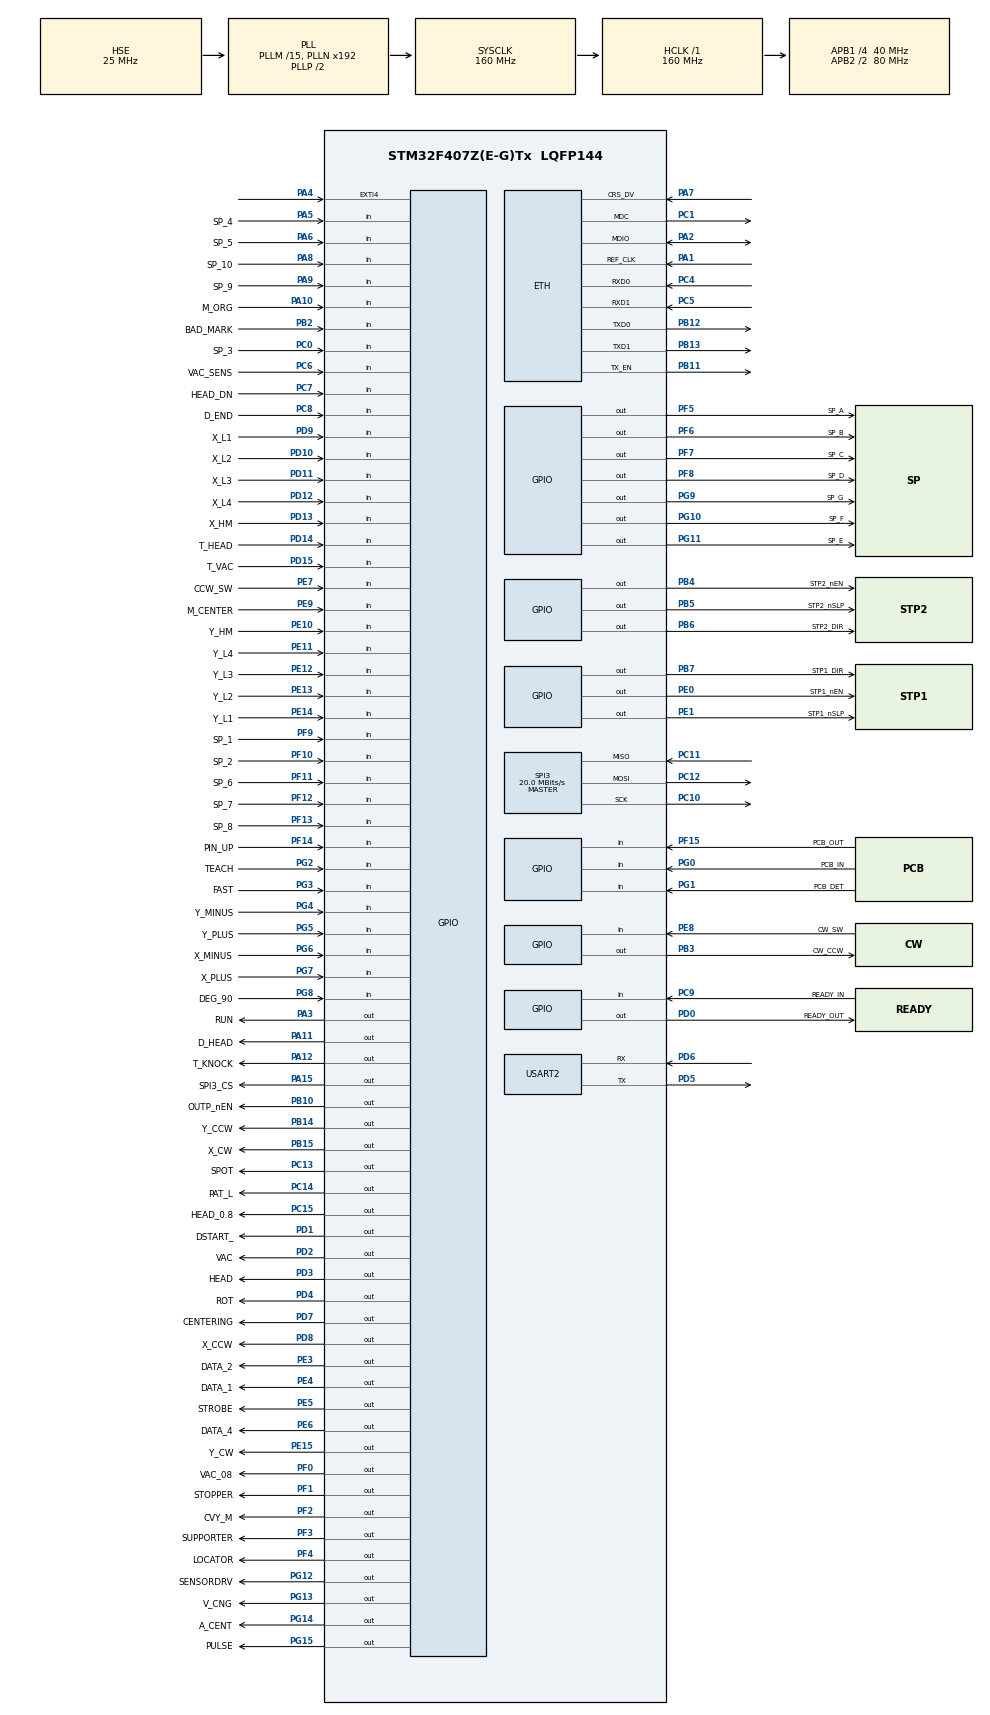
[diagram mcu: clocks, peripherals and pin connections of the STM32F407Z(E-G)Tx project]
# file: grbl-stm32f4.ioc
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ETH.MediaInterface=ETH_MEDIA_INTERFACE_RMII
Mcu.Family=STM32F4
Mcu.Name=STM32F407Z(E-G)Tx
Mcu.Package=LQFP144
NVIC.ETH_WKUP_IRQn=true\:0\:0\:false\:false\:true\:true\:true
NVIC.PriorityGroup=NVIC_PRIORITYGROUP_4
NVIC.TIM2_IRQn=true\:0\:0\:false\:false\:true\:true\:true
NVIC.TIM3_IRQn=true\:0\:0\:false\:false\:true\:true\:true
NVIC.TIM8_TRG_COM_TIM14_IRQn=true\:0\:0\:false\:false\:true\:true\:true
NVIC.USART2_IRQn=true\:0\:0\:false\:false\:true\:true\:true
PA1.Mode=RMII
PA1.Signal=ETH_REF_CLK
PA10.GPIO_Label=M_ORG
PA10.GPIO_PuPd=GPIO_PULLUP
PA10.Signal=GPIO_Input
PA11.GPIO_Label=D_HEAD
PA11.Signal=GPIO_Output
PA12.GPIO_Label=T_KNOCK
PA12.Signal=GPIO_Output
PA13.Mode=Serial_Wire
PA13.Signal=SYS_JTMS-SWDIO
PA14.Mode=Serial_Wire
PA14.Signal=SYS_JTCK-SWCLK
PA15.GPIO_Label=SPI3_CS
PA15.Signal=GPIO_Output
PA2.Mode=RMII
PA2.Signal=ETH_MDIO
PA3.GPIO_Label=RUN
PA3.Signal=GPIO_Output
PA4.Signal=GPXTI4
PA5.GPIO_Label=SP_4
PA5.GPIO_PuPd=GPIO_PULLUP
PA5.Signal=GPIO_Input
PA6.GPIO_Label=SP_5
PA6.GPIO_PuPd=GPIO_PULLUP
PA6.Signal=GPIO_Input
PA7.Mode=RMII
PA7.Signal=ETH_CRS_DV
PA8.GPIO_Label=SP_10
PA8.GPIO_PuPd=GPIO_PULLUP
PA8.Signal=GPIO_Input
PA9.GPIO_Label=SP_9
PA9.GPIO_PuPd=GPIO_PULLUP
PA9.Signal=GPIO_Input
PB10.GPIO_Label=OUTP_nEN
PB10.Signal=GPIO_Output
PB11.Mode=RMII
PB11.Signal=ETH_TX_EN
PB12.Mode=RMII
PB12.Signal=ETH_TXD0
PB13.Mode=RMII
PB13.Signal=ETH_TXD1
PB14.GPIO_Label=Y_CCW
PB14.GPIO_Speed=GPIO_SPEED_FREQ_VERY_HIGH
PB14.PinState=GPIO_PIN_SET
PB14.Signal=GPIO_Output
PB15.GPIO_Label=X_CW
PB15.GPIO_Speed=GPIO_SPEED_FREQ_VERY_HIGH
PB15.PinState=GPIO_PIN_SET
PB15.Signal=GPIO_Output
PB2.GPIO_Label=BAD_MARK
PB2.GPIO_PuPd=GPIO_PULLUP
PB2.Signal=GPIO_Input
PB3.GPIO_Label=CW_CCW
PB3.Signal=GPIO_Output
PB4.GPIO_Label=STP2_nEN
PB4.Signal=GPIO_Output
PB5.GPIO_Label=STP2_nSLP
PB5.Signal=GPIO_Output
PB6.GPIO_Label=STP2_DIR
PB6.Signal=GPIO_Output
PB7.GPIO_Label=STP1_DIR
PB7.Signal=GPIO_Output
PB8.GPIO_Label=STP2_STP
PB8.Signal=S_TIM4_CH3
PB9.GPIO_Label=STP1_STP
PB9.Signal=S_TIM4_CH4
PC0.GPIO_Label=SP_3
PC0.GPIO_PuPd=GPIO_PULLUP
PC0.Signal=GPIO_Input
PC1.Mode=RMII
PC1.Signal=ETH_MDC
PC10.Mode=Full_Duplex_Master
PC10.Signal=SPI3_SCK
PC11.Mode=Full_Duplex_Master
PC11.Signal=SPI3_MISO
PC12.Mode=Full_Duplex_Master
PC12.Signal=SPI3_MOSI
PC13-ANTI_TAMP.GPIO_Label=SPOT
PC13-ANTI_TAMP.Signal=GPIO_Output
PC14-OSC32_IN.GPIO_Label=PAT_L
PC14-OSC32_IN.Signal=GPIO_Output
PC15-OSC32_OUT.GPIO_Label=HEAD_0.8
PC15-OSC32_OUT.Signal=GPIO_Output
PC4.Mode=RMII
PC4.Signal=ETH_RXD0
PC5.Mode=RMII
PC5.Signal=ETH_RXD1
PC6.GPIO_Label=VAC_SENS
PC6.GPIO_PuPd=GPIO_PULLUP
PC6.Signal=GPIO_Input
PC7.GPIO_Label=HEAD_DN
PC7.GPIO_PuPd=GPIO_PULLUP
PC7.Signal=GPIO_Input
PC8.GPIO_Label=D_END
PC8.GPIO_PuPd=GPIO_PULLUP
PC8.Signal=GPIO_Input
PC9.GPIO_Label=READY_IN
PC9.GPIO_PuPd=GPIO_PULLUP
PC9.Signal=GPIO_Input
PD0.GPIO_Label=READY_OUT
PD0.Signal=GPIO_Output
PD1.GPIO_Label=DSTART_
PD1.Signal=GPIO_Output
PD10.GPIO_Label=X_L2
PD10.GPIO_PuPd=GPIO_PULLUP
PD10.Signal=GPIO_Input
PD11.GPIO_Label=X_L3
PD11.GPIO_PuPd=GPIO_PULLUP
PD11.Signal=GPIO_Input
PD12.GPIO_Label=X_L4
PD12.GPIO_PuPd=GPIO_PULLUP
PD12.Signal=GPIO_Input
PD13.GPIO_Label=X_HM
PD13.GPIO_PuPd=GPIO_PULLUP
PD13.Signal=GPIO_Input
PD14.GPIO_Label=T_HEAD
PD14.GPIO_PuPd=GPIO_PULLUP
PD14.Signal=GPIO_Input
PD15.GPIO_Label=T_VAC
PD15.GPIO_PuPd=GPIO_PULLUP
PD15.Signal=GPIO_Input
PD2.GPIO_Label=VAC
PD2.GPIO_PuPd=GPIO_NOPULL
PD2.Signal=GPIO_Output
PD3.GPIO_Label=HEAD
PD3.Signal=GPIO_Output
PD4.GPIO_Label=ROT
PD4.Signal=GPIO_Output
PD5.Mode=Asynchronous
PD5.Signal=USART2_TX
PD6.Mode=Asynchronous
PD6.Signal=USART2_RX
PD7.GPIO_Label=CENTERING
PD7.Signal=GPIO_Output
PD8.GPIO_Label=X_CCW
PD8.GPIO_Speed=GPIO_SPEED_FREQ_VERY_HIGH
PD8.PinState=GPIO_PIN_SET
PD8.Signal=GPIO_Output
PD9.GPIO_Label=X_L1
PD9.GPIO_PuPd=GPIO_PULLUP
PD9.Signal=GPIO_Input
PE0.GPIO_Label=STP1_nEN
PE0.Signal=GPIO_Output
PE1.GPIO_Label=STP1_nSLP
PE1.Signal=GPIO_Output
PE10.GPIO_Label=Y_HM
PE10.GPIO_PuPd=GPIO_PULLUP
PE10.Signal=GPIO_Input
PE11.GPIO_Label=Y_L4
PE11.GPIO_PuPd=GPIO_PULLUP
PE11.Signal=GPIO_Input
PE12.GPIO_Label=Y_L3
PE12.GPIO_PuPd=GPIO_PULLUP
PE12.Signal=GPIO_Input
PE13.GPIO_Label=Y_L2
PE13.GPIO_PuPd=GPIO_PULLUP
PE13.Signal=GPIO_Input
PE14.GPIO_Label=Y_L1
PE14.GPIO_PuPd=GPIO_PULLUP
PE14.Signal=GPIO_Input
PE15.GPIO_Label=Y_CW
PE15.GPIO_Speed=GPIO_SPEED_FREQ_VERY_HIGH
PE15.PinState=GPIO_PIN_SET
PE15.Signal=GPIO_Output
PE3.GPIO_Label=DATA_2
PE3.Signal=GPIO_Output
PE4.GPIO_Label=DATA_1
PE4.Signal=GPIO_Output
PE5.GPIO_Label=STROBE
PE5.Signal=GPIO_Output
PE6.GPIO_Label=DATA_4
PE6.Signal=GPIO_Output
PE7.GPIO_Label=CCW_SW
PE7.GPIO_PuPd=GPIO_PULLUP
PE7.Signal=GPIO_Input
PE8.GPIO_Label=CW_SW
PE8.GPIO_PuPd=GPIO_PULLUP
PE8.Signal=GPIO_Input
PE9.GPIO_Label=M_CENTER
PE9.GPIO_PuPd=GPIO_PULLUP
PE9.Signal=GPIO_Input
PF0.GPIO_Label=VAC_08
PF0.Signal=GPIO_Output
PF1.GPIO_Label=STOPPER
PF1.Signal=GPIO_Output
PF10.GPIO_Label=SP_2
PF10.GPIO_PuPd=GPIO_PULLUP
PF10.Signal=GPIO_Input
PF11.GPIO_Label=SP_6
PF11.GPIO_PuPd=GPIO_PULLUP
PF11.Signal=GPIO_Input
PF12.GPIO_Label=SP_7
PF12.GPIO_PuPd=GPIO_PULLUP
PF12.Signal=GPIO_Input
PF13.GPIO_Label=SP_8
PF13.GPIO_PuPd=GPIO_PULLUP
PF13.Signal=GPIO_Input
PF14.GPIO_Label=PIN_UP
PF14.GPIO_PuPd=GPIO_PULLUP
PF14.Signal=GPIO_Input
PF15.GPIO_Label=PCB_OUT
PF15.GPIO_PuPd=GPIO_PULLUP
PF15.Signal=GPIO_Input
PF2.GPIO_Label=CVY_M
PF2.Signal=GPIO_Output
PF3.GPIO_Label=SUPPORTER
PF3.Signal=GPIO_Output
PF4.GPIO_Label=LOCATOR
PF4.Signal=GPIO_Output
PF5.GPIO_Label=SP_A
PF5.Signal=GPIO_Output
PF6.GPIO_Label=SP_B
PF6.Signal=GPIO_Output
PF7.GPIO_Label=SP_C
PF7.Signal=GPIO_Output
PF8.GPIO_Label=SP_D
PF8.Signal=GPIO_Output
PF9.GPIO_Label=SP_1
PF9.GPIO_PuPd=GPIO_PULLUP
PF9.Signal=GPIO_Input
PG0.GPIO_Label=PCB_IN
PG0.GPIO_PuPd=GPIO_PULLUP
PG0.Signal=GPIO_Input
PG1.GPIO_Label=PCB_DET
PG1.GPIO_PuPd=GPIO_PULLUP
PG1.Signal=GPIO_Input
PG10.GPIO_Label=SP_F
PG10.Signal=GPIO_Output
PG11.GPIO_Label=SP_E
PG11.Signal=GPIO_Output
PG12.GPIO_Label=SENSORDRV
PG12.Signal=GPIO_Output
PG13.GPIO_Label=V_CNG
PG13.Signal=GPIO_Output
PG14.GPIO_Label=A_CENT
PG14.Signal=GPIO_Output
PG15.GPIO_Label=PULSE
PG15.Signal=GPIO_Output
PG2.GPIO_Label=TEACH
PG2.GPIO_PuPd=GPIO_PULLUP
PG2.Signal=GPIO_Input
PG3.GPIO_Label=FAST
PG3.GPIO_PuPd=GPIO_PULLUP
PG3.Signal=GPIO_Input
PG4.GPIO_Label=Y_MINUS
PG4.GPIO_PuPd=GPIO_PULLUP
PG4.Signal=GPIO_Input
PG5.GPIO_Label=Y_PLUS
PG5.GPIO_PuPd=GPIO_PULLUP
PG5.Signal=GPIO_Input
PG6.GPIO_Label=X_MINUS
PG6.GPIO_PuPd=GPIO_PULLUP
PG6.Signal=GPIO_Input
PG7.GPIO_Label=X_PLUS
PG7.GPIO_PuPd=GPIO_PULLUP
PG7.Signal=GPIO_Input
PG8.GPIO_Label=DEG_90
PG8.GPIO_PuPd=GPIO_PULLUP
PG8.Signal=GPIO_Input
PG9.GPIO_Label=SP_G
PG9.Signal=GPIO_Output
PH0-OSC_IN.Mode=HSE-External-Oscillator
PH0-OSC_IN.Signal=RCC_OSC_IN
PH1-OSC_OUT.Mode=HSE-External-Oscillator
PH1-OSC_OUT.Signal=RCC_OSC_OUT
ProjectManager.HeapSize=0x200
ProjectManager.StackSize=0x400
ProjectManager.TargetToolchain=STM32CubeIDE
RCC.48MHZClocksFreq_Value=80000000
RCC.AHBFreq_Value=160000000
RCC.APB1CLKDivider=RCC_HCLK_DIV4
RCC.APB1Freq_Value=40000000
RCC.APB1TimFreq_Value=80000000
RCC.APB2CLKDivider=RCC_HCLK_DIV2
RCC.APB2Freq_Value=80000000
RCC.APB2TimFreq_Value=160000000
RCC.CortexFreq_Value=160000000
RCC.HCLKFreq_Value=160000000
RCC.HSE_VALUE=25000000
RCC.HSI_VALUE=16000000
RCC.LSE_VALUE=32768
RCC.PLLM=15
RCC.PLLSourceVirtual=RCC_PLLSOURCE_HSE
RCC.SYSCLKFreq_VALUE=160000000
RCC.SYSCLKSource=RCC_SYSCLKSOURCE_PLLCLK
RCC.VCOOutputFreq_Value=320000000
SH.S_TIM4_CH3.0=TIM4_CH3
SH.S_TIM4_CH4.0=TIM4_CH4
SPI3.BaudRatePrescaler=SPI_BAUDRATEPRESCALER_2
SPI3.CalculateBaudRate=20.0 MBits/s
SPI3.Direction=SPI_DIRECTION_2LINES
SPI3.Mode=SPI_MODE_MASTER
SPI3.VirtualType=VM_MASTER
TIM14.AutoReloadPreload=TIM_AUTORELOAD_PRELOAD_ENABLE
TIM14.ClockDivision=TIM_CLOCKDIVISION_DIV1
TIM14.Period=1000
TIM14.Prescaler=100
TIM2.ClockDivision=TIM_CLOCKDIVISION_DIV1
TIM2.Period=1000
TIM3.AutoReloadPreload=TIM_AUTORELOAD_PRELOAD_DISABLE
TIM3.ClockDivision=TIM_CLOCKDIVISION_DIV1
TIM3.Period=10
TIM3.Prescaler=16
USART2.VirtualMode=VM_ASYNC
VP_TIM14_VS_ClockSourceINT.Mode=Enable_Timer
VP_TIM2_VS_ClockSourceINT.Mode=Internal
VP_TIM2_VS_ClockSourceITR.Mode=TriggerSource_ITR0
VP_TIM3_VS_ClockSourceINT.Mode=Internal
VP_TIM3_VS_ClockSourceITR.Mode=TriggerSource_ITR0
board=custom

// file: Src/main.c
/* USER CODE BEGIN Header */
/**
 ******************************************************************************
 * @file           : main.c
 * @brief          : Main program body
 ******************************************************************************
 * @attention
 *
 * <h2><center>&copy; Copyright (c) 2019 STMicroelectronics.
 * All rights reserved.</center></h2>
 *
 * This software component is licensed by ST under BSD 3-Clause license,
 * the "License"; You may not use this file except in compliance with the
 * License. You may obtain a copy of the License at:
 *                        opensource.org/licenses/BSD-3-Clause
 *
 ******************************************************************************

 main.c - An embedded CNC Controller with rs274/ngc (g-code) support
 Part of Grbl-Advanced

 Copyright (c) 2011-2016 Sungeun K. Jeon for Gnea Research LLC
 Copyright (c) 2009-2011 Simen Svale Skogsrud
 Copyright (c)	2017 Patrick F.

 Grbl-Advanced is free software: you can redistribute it and/or modify
 it under the terms of the GNU General Public License as published by
 the Free Software Foundation, either version 3 of the License, or
 (at your option) any later version.
 Grbl-Advanced is distributed in the hope that it will be useful,
 but WITHOUT ANY WARRANTY; without even the implied warranty of
 MERCHANTABILITY or FITNESS FOR A PARTICULAR PURPOSE.  See the
 GNU General Public License for more details.
 You should have received a copy of the GNU General Public License
 along with Grbl-Advanced.  If not, see <http://www.gnu.org/licenses/>.

 */
/* USER CODE END Header */

#include "main.h"

/* USER CODE BEGIN Includes */
#include "SEGGER_SYSVIEW.h"

#include <stdio.h>
#include <stdlib.h>
#include <stdint.h>

#include "system.h"
#include "grbl.h"

#include "print.h"

#define ACTUATOR_LIMIT 31 // define 31 output pins for hardware M42 command
#include "cpu_map_stm32.h"
/* USER CODE END Includes */

ETH_HandleTypeDef heth;

SPI_HandleTypeDef hspi3;

TIM_HandleTypeDef htim2;
TIM_HandleTypeDef htim3;
TIM_HandleTypeDef htim14;

UART_HandleTypeDef huart2;

/* USER CODE BEGIN PV */
system_t sys;
int32_t sys_position[N_AXIS]; // Real-time machine (aka home) position vector in steps.
int32_t sys_probe_position[N_AXIS]; // Last probe position in machine coordinates and steps.
volatile uint8_t sys_probe_state; // Probing state value.  Used to coordinate the probing cycle with stepper ISR.
volatile uint8_t sys_rt_exec_state; // Global realtime executor bitflag variable for state management. See EXEC bitmasks.
volatile uint8_t sys_rt_exec_alarm; // Global realtime executor bitflag variable for setting various alarms.
volatile uint8_t sys_rt_exec_motion_override; // Global realtime executor bitflag variable for motion-based overrides.
volatile uint8_t sys_rt_exec_accessory_override; // Global realtime executor bitflag variable for spindle/coolant overrides.
#ifdef DEBUG
volatile uint8_t sys_rt_exec_debug;
#endif
uint8_t rx_byte;
/* USER CODE END PV */

void SystemClock_Config(void);
static void MX_GPIO_Init(void);
static void MX_ETH_Init(void);
static void MX_SPI3_Init(void);
static void MX_USART2_UART_Init(void);
static void MX_TIM2_Init(void);
static void MX_TIM3_Init(void);
static void MX_TIM14_Init(void);

/* USER CODE BEGIN 0 */
// Actuators that can be controlled with M42
const gpio actuators[] = {
/* 0 */	{.port = VAC_GPIO_Port, .pin= VAC_Pin},
/* 1 */	{.port = HEAD_GPIO_Port, .pin= HEAD_Pin},
/* 2 */	{.port = ROT_GPIO_Port, .pin= ROT_Pin},
/* 3 */	{.port = CENTERING_GPIO_Port, .pin= CENTERING_Pin},
/* 4 */	{.port = STROBE_GPIO_Port, .pin = STROBE_Pin},
/* 5 */	{.port = STOPPER_GPIO_Port, .pin = STOPPER_Pin},
/* 6 */	{.port = DATA_1_GPIO_Port, .pin = DATA_1_Pin},
/* 7 */	{.port = DATA_2_GPIO_Port, .pin = DATA_2_Pin},
/* 8 */	{.port = DATA_4_GPIO_Port, .pin = DATA_4_Pin},
/* 9 */	{.port = VAC_08_GPIO_Port, .pin = VAC_08_Pin},
/* 10 */{.port = HEAD_0_8_GPIO_Port, .pin = HEAD_0_8_Pin},
/* 11 */{.port = D_HEAD_GPIO_Port, .pin = D_HEAD_Pin},
/* 12 */{.port = T_KNOCK_GPIO_Port, .pin = T_KNOCK_Pin},
/* 13 */{.port = SPOT_GPIO_Port, .pin = SPOT_Pin},
/* 14 */{.port = PAT_L_GPIO_Port, .pin = PAT_L_Pin},
/* 15 */{.port = READY_OUT_GPIO_Port, .pin = READY_OUT_Pin},
/* 16 */{.port = DSTART__GPIO_Port, .pin = DSTART__Pin},
/* 17 */{.port = CVY_M_GPIO_Port, .pin = CVY_M_Pin},
/* 18 */{.port = SUPPORTER_GPIO_Port, .pin = SUPPORTER_Pin},
/* 19 */{.port = LOCATOR_GPIO_Port, .pin = LOCATOR_Pin},
/* 20 */{.port = SP_A_GPIO_Port, .pin = SP_A_Pin},
/* 21 */{.port = SP_B_GPIO_Port, .pin = SP_B_Pin},
/* 22 */{.port = SP_C_GPIO_Port, .pin = SP_C_Pin},
/* 23 */{.port = SP_D_GPIO_Port, .pin = SP_D_Pin},
/* 24 */{.port = SP_E_GPIO_Port, .pin = SP_E_Pin},
/* 25 */{.port = SP_F_GPIO_Port, .pin = SP_F_Pin},
/* 26 */{.port = SP_G_GPIO_Port, .pin = SP_G_Pin},
/* 27 */{.port = SENSORDRV_GPIO_Port, .pin = SENSORDRV_Pin},
/* 28 */{.port = V_CNG_GPIO_Port, .pin = V_CNG_Pin},
/* 29 */{.port = A_CENT_GPIO_Port, .pin = A_CENT_Pin},
/* 30 */{.port = PULSE_GPIO_Port, .pin = PULSE_Pin},
};
const uint8_t actuators_limit = sizeof(actuators)/sizeof(gpio);

const gpio sensors[] = {
		{.port = VAC_SENS_GPIO_Port, .pin = VAC_SENS_Pin, .key = 'v'},
		{.port = T_VAC_GPIO_Port, .pin = T_VAC_Pin, .key = 'V'},
		{.port = T_HEAD_GPIO_Port, .pin = T_HEAD_Pin, .key = 'h'},
		{.port = BAD_MARK_GPIO_Port, .pin = BAD_MARK_Pin, .key = 'b'},
		{.port = CCW_SW_GPIO_Port, .pin = CCW_SW_Pin, .key = 'C'},
		{.port = CW_SW_GPIO_Port, .pin = CW_CCW_Pin, .key = 'c'},
		{.port = D_END_GPIO_Port, .pin = D_END_Pin, .key = 'd'},
		{.port = DEG_90_GPIO_Port, .pin = DEG_90_Pin, .key = 'D'},
		{.port = M_CENTER_GPIO_Port, .pin = M_CENTER_Pin, .key = 'm'},
		{.port = M_ORG_GPIO_Port, .pin = M_ORG_Pin, .key = 'M'},
		{.port = PCB_DET_GPIO_Port, .pin = PCB_DET_Pin, .key = 'P'},
		{.port = PCB_IN_GPIO_Port, .pin = PCB_IN_Pin, .key = 'I'},
		{.port = PCB_OUT_GPIO_Port, .pin = PCB_OUT_Pin, .key = 'O'},
		{.port = PIN_UP_GPIO_Port, .pin = PIN_UP_Pin, .key = 'u'},
		{.port = READY_IN_GPIO_Port, .pin = READY_IN_Pin, .key = 'r'},
};
const uint8_t sensors_limit = sizeof(sensors)/sizeof(gpio);
/* USER CODE END 0 */

int main(void)
{

  /* MCU Configuration--------------------------------------------------------*/

  /* Reset of all peripherals, Initializes the Flash interface and the Systick. */
  HAL_Init();

  /* Configure the system clock */
  SystemClock_Config();

  /* Initialize all configured peripherals */
  MX_GPIO_Init();
  MX_ETH_Init();
  MX_SPI3_Init();
  MX_USART2_UART_Init();
  MX_TIM2_Init();
  MX_TIM3_Init();
  MX_TIM14_Init();
  /* USER CODE BEGIN 2 */

  SEGGER_SYSVIEW_Conf(); // Configure and initialize SystemView
  SEGGER_SYSVIEW_OnIdle();

  // Initialize grbl system upon power-up.
  settings_init(); // Load Grbl settings from EEPROM
  stepper_init();  // Configure stepper pins and interrupt timers
  system_init();   // Configure pinout pins and pin-change interrupt

	memset(sys_position, 0, sizeof(sys_position)); // Clear machine position.
	// Initialize system state.
#ifdef FORCE_INITIALIZATION_ALARM
	// Force Grbl into an ALARM state upon a power-cycle or hard reset.
	sys.state = STATE_ALARM;
#else
	sys.state = STATE_IDLE;
#endif

	// Check for power-up and set system alarm if homing is enabled to force homing cycle
	// by setting Grbl's alarm state. Alarm locks out all g-code commands, including the
	// startup scripts, but allows access to settings and internal commands. Only a homing
	// cycle '$H' or kill alarm locks '$X' will disable the alarm.
	// NOTE: The startup script will run after successful completion of the homing cycle, but
	// not after disabling the alarm locks. Prevents motion startup blocks from crashing into
	// things uncontrollably. Very bad.
#ifdef HOMING_INIT_LOCK
	if (bit_istrue(settings.flags, BITFLAG_HOMING_ENABLE)) {
		sys.state = STATE_ALARM;
	}
#endif

	// Grbl initialization loop upon power-up or a system abort. For the latter, all processes
	// will return to this loop to be cleanly re-initialized.

	// Reset system variables.
	uint8_t prior_state = sys.state;
	memset(&sys, 0, sizeof(system_t)); // Clear system struct variable.
	sys.state = prior_state;
	sys.f_override = DEFAULT_FEED_OVERRIDE;  // Set to 100%
	sys.r_override = DEFAULT_RAPID_OVERRIDE; // Set to 100%
	sys.spindle_speed_ovr = DEFAULT_SPINDLE_SPEED_OVERRIDE; // Set to 100%
	memset(sys_probe_position, 0, sizeof(sys_probe_position)); // Clear probe position.
	sys_probe_state = 0;
	sys_rt_exec_state = 0;
	sys_rt_exec_alarm = 0;
	sys_rt_exec_motion_override = 0;
	sys_rt_exec_accessory_override = 0;

	// Reset Grbl primary systems.
	serial_reset_read_buffer(); // Clear serial read buffer
	gc_init(); // Set g-code parser to default state
	//spindle_init();
	//coolant_init();
	//limits_init(); // Done in CubeMX
	//probe_init();
	plan_reset(); // Clear block buffer and planner variables
	st_reset(); // Clear stepper subsystem variables.

	// Sync cleared gcode and planner positions to current system position.
	plan_sync_position();
	gc_sync_position();

	// Print welcome message. Indicates an initialization has occured at power-up or with a reset.
	report_init_message();
	HAL_UART_Receive_IT(&huart2, &rx_byte, 1);
  /* USER CODE END 2 */

  /* Infinite loop */
  /* USER CODE BEGIN WHILE */
	// Start Grbl main loop. Processes program inputs and executes them.
	protocol_main_loop();
    /* USER CODE END WHILE */

}

void SystemClock_Config(void)
{
  RCC_OscInitTypeDef RCC_OscInitStruct = {0};
  RCC_ClkInitTypeDef RCC_ClkInitStruct = {0};

  /** Configure the main internal regulator output voltage
  */
  __HAL_RCC_PWR_CLK_ENABLE();
  __HAL_PWR_VOLTAGESCALING_CONFIG(PWR_REGULATOR_VOLTAGE_SCALE1);
  /** Initializes the CPU, AHB and APB busses clocks
  */
  RCC_OscInitStruct.OscillatorType = RCC_OSCILLATORTYPE_HSE;
  RCC_OscInitStruct.HSEState = RCC_HSE_ON;
  RCC_OscInitStruct.PLL.PLLState = RCC_PLL_ON;
  RCC_OscInitStruct.PLL.PLLSource = RCC_PLLSOURCE_HSE;
  RCC_OscInitStruct.PLL.PLLM = 15;
  RCC_OscInitStruct.PLL.PLLN = 192;
  RCC_OscInitStruct.PLL.PLLP = RCC_PLLP_DIV2;
  RCC_OscInitStruct.PLL.PLLQ = 4;
  if (HAL_RCC_OscConfig(&RCC_OscInitStruct) != HAL_OK)
  {
    Error_Handler();
  }
  /** Initializes the CPU, AHB and APB busses clocks
  */
  RCC_ClkInitStruct.ClockType = RCC_CLOCKTYPE_HCLK|RCC_CLOCKTYPE_SYSCLK
                              |RCC_CLOCKTYPE_PCLK1|RCC_CLOCKTYPE_PCLK2;
  RCC_ClkInitStruct.SYSCLKSource = RCC_SYSCLKSOURCE_PLLCLK;
  RCC_ClkInitStruct.AHBCLKDivider = RCC_SYSCLK_DIV1;
  RCC_ClkInitStruct.APB1CLKDivider = RCC_HCLK_DIV4;
  RCC_ClkInitStruct.APB2CLKDivider = RCC_HCLK_DIV2;

  if (HAL_RCC_ClockConfig(&RCC_ClkInitStruct, FLASH_LATENCY_5) != HAL_OK)
  {
    Error_Handler();
  }
}

static void MX_ETH_Init(void)
{

  heth.Instance = ETH;
  heth.Init.AutoNegotiation = ETH_AUTONEGOTIATION_ENABLE;
  heth.Init.PhyAddress = LAN8742A_PHY_ADDRESS;
  heth.Init.MACAddr[0] =   0x00;
  heth.Init.MACAddr[1] =   0x80;
  heth.Init.MACAddr[2] =   0xE1;
  heth.Init.MACAddr[3] =   0x00;
  heth.Init.MACAddr[4] =   0x00;
  heth.Init.MACAddr[5] =   0x00;
  heth.Init.RxMode = ETH_RXPOLLING_MODE;
  heth.Init.ChecksumMode = ETH_CHECKSUM_BY_HARDWARE;
  heth.Init.MediaInterface = ETH_MEDIA_INTERFACE_RMII;

  if (HAL_ETH_Init(&heth) != HAL_OK)
  {
    Error_Handler();
  }

}

static void MX_SPI3_Init(void)
{

  /* SPI3 parameter configuration*/
  hspi3.Instance = SPI3;
  hspi3.Init.Mode = SPI_MODE_MASTER;
  hspi3.Init.Direction = SPI_DIRECTION_2LINES;
  hspi3.Init.DataSize = SPI_DATASIZE_8BIT;
  hspi3.Init.CLKPolarity = SPI_POLARITY_LOW;
  hspi3.Init.CLKPhase = SPI_PHASE_1EDGE;
  hspi3.Init.NSS = SPI_NSS_SOFT;
  hspi3.Init.BaudRatePrescaler = SPI_BAUDRATEPRESCALER_2;
  hspi3.Init.FirstBit = SPI_FIRSTBIT_MSB;
  hspi3.Init.TIMode = SPI_TIMODE_DISABLE;
  hspi3.Init.CRCCalculation = SPI_CRCCALCULATION_DISABLE;
  hspi3.Init.CRCPolynomial = 10;
  if (HAL_SPI_Init(&hspi3) != HAL_OK)
  {
    Error_Handler();
  }

}

static void MX_TIM2_Init(void)
{

  TIM_ClockConfigTypeDef sClockSourceConfig = {0};
  TIM_SlaveConfigTypeDef sSlaveConfig = {0};
  TIM_MasterConfigTypeDef sMasterConfig = {0};

  htim2.Instance = TIM2;
  htim2.Init.Prescaler = 0;
  htim2.Init.CounterMode = TIM_COUNTERMODE_UP;
  htim2.Init.Period = 1000;
  htim2.Init.ClockDivision = TIM_CLOCKDIVISION_DIV1;
  htim2.Init.AutoReloadPreload = TIM_AUTORELOAD_PRELOAD_DISABLE;
  if (HAL_TIM_Base_Init(&htim2) != HAL_OK)
  {
    Error_Handler();
  }
  sClockSourceConfig.ClockSource = TIM_CLOCKSOURCE_INTERNAL;
  if (HAL_TIM_ConfigClockSource(&htim2, &sClockSourceConfig) != HAL_OK)
  {
    Error_Handler();
  }
  sSlaveConfig.SlaveMode = TIM_SLAVEMODE_DISABLE;
  sSlaveConfig.InputTrigger = TIM_TS_ITR0;
  if (HAL_TIM_SlaveConfigSynchro(&htim2, &sSlaveConfig) != HAL_OK)
  {
    Error_Handler();
  }
  sMasterConfig.MasterOutputTrigger = TIM_TRGO_RESET;
  sMasterConfig.MasterSlaveMode = TIM_MASTERSLAVEMODE_DISABLE;
  if (HAL_TIMEx_MasterConfigSynchronization(&htim2, &sMasterConfig) != HAL_OK)
  {
    Error_Handler();
  }
  /* USER CODE BEGIN TIM2_Init 2 */
HAL_TIM_Base_Start_IT(&htim2);
  /* USER CODE END TIM2_Init 2 */

}

static void MX_TIM3_Init(void)
{

  TIM_ClockConfigTypeDef sClockSourceConfig = {0};
  TIM_SlaveConfigTypeDef sSlaveConfig = {0};
  TIM_MasterConfigTypeDef sMasterConfig = {0};

  htim3.Instance = TIM3;
  htim3.Init.Prescaler = 2;
  htim3.Init.CounterMode = TIM_COUNTERMODE_UP;
  htim3.Init.Period = 10;
  htim3.Init.ClockDivision = TIM_CLOCKDIVISION_DIV1;
  htim3.Init.AutoReloadPreload = TIM_AUTORELOAD_PRELOAD_DISABLE;
  if (HAL_TIM_Base_Init(&htim3) != HAL_OK)
  {
    Error_Handler();
  }
  sClockSourceConfig.ClockSource = TIM_CLOCKSOURCE_INTERNAL;
  if (HAL_TIM_ConfigClockSource(&htim3, &sClockSourceConfig) != HAL_OK)
  {
    Error_Handler();
  }
  sSlaveConfig.SlaveMode = TIM_SLAVEMODE_DISABLE;
  sSlaveConfig.InputTrigger = TIM_TS_ITR0;
  if (HAL_TIM_SlaveConfigSynchro(&htim3, &sSlaveConfig) != HAL_OK)
  {
    Error_Handler();
  }
  sMasterConfig.MasterOutputTrigger = TIM_TRGO_RESET;
  sMasterConfig.MasterSlaveMode = TIM_MASTERSLAVEMODE_DISABLE;
  if (HAL_TIMEx_MasterConfigSynchronization(&htim3, &sMasterConfig) != HAL_OK)
  {
    Error_Handler();
  }
  /* USER CODE BEGIN TIM3_Init 2 */
HAL_TIM_Base_Start_IT(&htim3);
  /* USER CODE END TIM3_Init 2 */

}

static void MX_TIM14_Init(void)
{

  htim14.Instance = TIM14;
  htim14.Init.Prescaler = 100;
  htim14.Init.CounterMode = TIM_COUNTERMODE_UP;
  htim14.Init.Period = 1000;
  htim14.Init.ClockDivision = TIM_CLOCKDIVISION_DIV1;
  htim14.Init.AutoReloadPreload = TIM_AUTORELOAD_PRELOAD_ENABLE;
  if (HAL_TIM_Base_Init(&htim14) != HAL_OK)
  {
    Error_Handler();
  }
  /* USER CODE BEGIN TIM14_Init 2 */
  HAL_TIM_Base_Start_IT(&htim14); // Enable the input latch timer
  /* USER CODE END TIM14_Init 2 */

}

static void MX_USART2_UART_Init(void)
{

  huart2.Instance = USART2;
  huart2.Init.BaudRate = 115200;
  huart2.Init.WordLength = UART_WORDLENGTH_8B;
  huart2.Init.StopBits = UART_STOPBITS_1;
  huart2.Init.Parity = UART_PARITY_NONE;
  huart2.Init.Mode = UART_MODE_TX_RX;
  huart2.Init.HwFlowCtl = UART_HWCONTROL_NONE;
  huart2.Init.OverSampling = UART_OVERSAMPLING_16;
  if (HAL_UART_Init(&huart2) != HAL_OK)
  {
    Error_Handler();
  }

}

static void MX_GPIO_Init(void)
{
  GPIO_InitTypeDef GPIO_InitStruct = {0};

  /* GPIO Ports Clock Enable */
  __HAL_RCC_GPIOE_CLK_ENABLE();
  __HAL_RCC_GPIOC_CLK_ENABLE();
  __HAL_RCC_GPIOF_CLK_ENABLE();
  __HAL_RCC_GPIOH_CLK_ENABLE();
  __HAL_RCC_GPIOA_CLK_ENABLE();
  __HAL_RCC_GPIOB_CLK_ENABLE();
  __HAL_RCC_GPIOG_CLK_ENABLE();
  __HAL_RCC_GPIOD_CLK_ENABLE();

  /*Configure GPIO pin Output Level */
  HAL_GPIO_WritePin(GPIOE, DATA_2_Pin|DATA_1_Pin|STROBE_Pin|DATA_4_Pin
                          |STP1_nEN_Pin|STP1_nSLP_Pin, GPIO_PIN_RESET);

  /*Configure GPIO pin Output Level */
  HAL_GPIO_WritePin(GPIOC, SPOT_Pin|PAT_L_Pin|HEAD_0_8_Pin, GPIO_PIN_RESET);

  /*Configure GPIO pin Output Level */
  HAL_GPIO_WritePin(GPIOF, VAC_08_Pin|STOPPER_Pin|CVY_M_Pin|SUPPORTER_Pin
                          |LOCATOR_Pin|SP_A_Pin|SP_B_Pin|SP_C_Pin
                          |SP_D_Pin, GPIO_PIN_RESET);

  /*Configure GPIO pin Output Level */
  HAL_GPIO_WritePin(GPIOA, RUN_Pin|D_HEAD_Pin|T_KNOCK_Pin|SPI3_CS_Pin, GPIO_PIN_RESET);

  /*Configure GPIO pin Output Level */
  HAL_GPIO_WritePin(Y_CW_GPIO_Port, Y_CW_Pin, GPIO_PIN_SET);

  /*Configure GPIO pin Output Level */
  HAL_GPIO_WritePin(GPIOB, OUTP_nEN_Pin|CW_CCW_Pin|STP2_nEN_Pin|STP2_nSLP_Pin
                          |STP2_DIR_Pin|STP1_DIR_Pin, GPIO_PIN_RESET);

  /*Configure GPIO pin Output Level */
  HAL_GPIO_WritePin(GPIOB, Y_CCW_Pin|X_CW_Pin, GPIO_PIN_SET);

  /*Configure GPIO pin Output Level */
  HAL_GPIO_WritePin(X_CCW_GPIO_Port, X_CCW_Pin, GPIO_PIN_SET);

  /*Configure GPIO pin Output Level */
  HAL_GPIO_WritePin(GPIOD, READY_OUT_Pin|DSTART__Pin|VAC_Pin|HEAD_Pin
                          |ROT_Pin|CENTERING_Pin, GPIO_PIN_RESET);

  /*Configure GPIO pin Output Level */
  HAL_GPIO_WritePin(GPIOG, SP_G_Pin|SP_F_Pin|SP_E_Pin|SENSORDRV_Pin
                          |V_CNG_Pin|A_CENT_Pin|PULSE_Pin, GPIO_PIN_RESET);

  /*Configure GPIO pins : DATA_2_Pin DATA_1_Pin STROBE_Pin DATA_4_Pin
                           STP1_nEN_Pin STP1_nSLP_Pin */
  GPIO_InitStruct.Pin = DATA_2_Pin|DATA_1_Pin|STROBE_Pin|DATA_4_Pin
                          |STP1_nEN_Pin|STP1_nSLP_Pin;
  GPIO_InitStruct.Mode = GPIO_MODE_OUTPUT_PP;
  GPIO_InitStruct.Pull = GPIO_NOPULL;
  GPIO_InitStruct.Speed = GPIO_SPEED_FREQ_LOW;
  HAL_GPIO_Init(GPIOE, &GPIO_InitStruct);

  /*Configure GPIO pins : SPOT_Pin PAT_L_Pin HEAD_0_8_Pin */
  GPIO_InitStruct.Pin = SPOT_Pin|PAT_L_Pin|HEAD_0_8_Pin;
  GPIO_InitStruct.Mode = GPIO_MODE_OUTPUT_PP;
  GPIO_InitStruct.Pull = GPIO_NOPULL;
  GPIO_InitStruct.Speed = GPIO_SPEED_FREQ_LOW;
  HAL_GPIO_Init(GPIOC, &GPIO_InitStruct);

  /*Configure GPIO pins : VAC_08_Pin STOPPER_Pin CVY_M_Pin SUPPORTER_Pin
                           LOCATOR_Pin SP_A_Pin SP_B_Pin SP_C_Pin
                           SP_D_Pin */
  GPIO_InitStruct.Pin = VAC_08_Pin|STOPPER_Pin|CVY_M_Pin|SUPPORTER_Pin
                          |LOCATOR_Pin|SP_A_Pin|SP_B_Pin|SP_C_Pin
                          |SP_D_Pin;
  GPIO_InitStruct.Mode = GPIO_MODE_OUTPUT_PP;
  GPIO_InitStruct.Pull = GPIO_NOPULL;
  GPIO_InitStruct.Speed = GPIO_SPEED_FREQ_LOW;
  HAL_GPIO_Init(GPIOF, &GPIO_InitStruct);

  /*Configure GPIO pins : SP_1_Pin SP_2_Pin SP_6_Pin SP_7_Pin
                           SP_8_Pin PIN_UP_Pin PCB_OUT_Pin */
  GPIO_InitStruct.Pin = SP_1_Pin|SP_2_Pin|SP_6_Pin|SP_7_Pin
                          |SP_8_Pin|PIN_UP_Pin|PCB_OUT_Pin;
  GPIO_InitStruct.Mode = GPIO_MODE_INPUT;
  GPIO_InitStruct.Pull = GPIO_PULLUP;
  HAL_GPIO_Init(GPIOF, &GPIO_InitStruct);

  /*Configure GPIO pins : SP_3_Pin VAC_SENS_Pin HEAD_DN_Pin D_END_Pin
                           READY_IN_Pin */
  GPIO_InitStruct.Pin = SP_3_Pin|VAC_SENS_Pin|HEAD_DN_Pin|D_END_Pin
                          |READY_IN_Pin;
  GPIO_InitStruct.Mode = GPIO_MODE_INPUT;
  GPIO_InitStruct.Pull = GPIO_PULLUP;
  HAL_GPIO_Init(GPIOC, &GPIO_InitStruct);

  /*Configure GPIO pins : RUN_Pin D_HEAD_Pin T_KNOCK_Pin SPI3_CS_Pin */
  GPIO_InitStruct.Pin = RUN_Pin|D_HEAD_Pin|T_KNOCK_Pin|SPI3_CS_Pin;
  GPIO_InitStruct.Mode = GPIO_MODE_OUTPUT_PP;
  GPIO_InitStruct.Pull = GPIO_NOPULL;
  GPIO_InitStruct.Speed = GPIO_SPEED_FREQ_LOW;
  HAL_GPIO_Init(GPIOA, &GPIO_InitStruct);

  /*Configure GPIO pin : PA4 */
  GPIO_InitStruct.Pin = GPIO_PIN_4;
  GPIO_InitStruct.Mode = GPIO_MODE_IT_RISING;
  GPIO_InitStruct.Pull = GPIO_NOPULL;
  HAL_GPIO_Init(GPIOA, &GPIO_InitStruct);

  /*Configure GPIO pins : SP_4_Pin SP_5_Pin SP_10_Pin SP_9_Pin
                           M_ORG_Pin */
  GPIO_InitStruct.Pin = SP_4_Pin|SP_5_Pin|SP_10_Pin|SP_9_Pin
                          |M_ORG_Pin;
  GPIO_InitStruct.Mode = GPIO_MODE_INPUT;
  GPIO_InitStruct.Pull = GPIO_PULLUP;
  HAL_GPIO_Init(GPIOA, &GPIO_InitStruct);

  /*Configure GPIO pin : BAD_MARK_Pin */
  GPIO_InitStruct.Pin = BAD_MARK_Pin;
  GPIO_InitStruct.Mode = GPIO_MODE_INPUT;
  GPIO_InitStruct.Pull = GPIO_PULLUP;
  HAL_GPIO_Init(BAD_MARK_GPIO_Port, &GPIO_InitStruct);

  /*Configure GPIO pins : PCB_IN_Pin PCB_DET_Pin TEACH_Pin FAST_Pin
                           Y_MINUS_Pin Y_PLUS_Pin X_MINUS_Pin X_PLUS_Pin
                           DEG_90_Pin */
  GPIO_InitStruct.Pin = PCB_IN_Pin|PCB_DET_Pin|TEACH_Pin|FAST_Pin
                          |Y_MINUS_Pin|Y_PLUS_Pin|X_MINUS_Pin|X_PLUS_Pin
                          |DEG_90_Pin;
  GPIO_InitStruct.Mode = GPIO_MODE_INPUT;
  GPIO_InitStruct.Pull = GPIO_PULLUP;
  HAL_GPIO_Init(GPIOG, &GPIO_InitStruct);

  /*Configure GPIO pins : CCW_SW_Pin CW_SW_Pin M_CENTER_Pin Y_HM_Pin
                           Y_L4_Pin Y_L3_Pin Y_L2_Pin Y_L1_Pin */
  GPIO_InitStruct.Pin = CCW_SW_Pin|CW_SW_Pin|M_CENTER_Pin|Y_HM_Pin
                          |Y_L4_Pin|Y_L3_Pin|Y_L2_Pin|Y_L1_Pin;
  GPIO_InitStruct.Mode = GPIO_MODE_INPUT;
  GPIO_InitStruct.Pull = GPIO_PULLUP;
  HAL_GPIO_Init(GPIOE, &GPIO_InitStruct);

  /*Configure GPIO pin : Y_CW_Pin */
  GPIO_InitStruct.Pin = Y_CW_Pin;
  GPIO_InitStruct.Mode = GPIO_MODE_OUTPUT_PP;
  GPIO_InitStruct.Pull = GPIO_NOPULL;
  GPIO_InitStruct.Speed = GPIO_SPEED_FREQ_VERY_HIGH;
  HAL_GPIO_Init(Y_CW_GPIO_Port, &GPIO_InitStruct);

  /*Configure GPIO pins : OUTP_nEN_Pin CW_CCW_Pin STP2_nEN_Pin STP2_nSLP_Pin
                           STP2_DIR_Pin STP1_DIR_Pin */
  GPIO_InitStruct.Pin = OUTP_nEN_Pin|CW_CCW_Pin|STP2_nEN_Pin|STP2_nSLP_Pin
                          |STP2_DIR_Pin|STP1_DIR_Pin;
  GPIO_InitStruct.Mode = GPIO_MODE_OUTPUT_PP;
  GPIO_InitStruct.Pull = GPIO_NOPULL;
  GPIO_InitStruct.Speed = GPIO_SPEED_FREQ_LOW;
  HAL_GPIO_Init(GPIOB, &GPIO_InitStruct);

  /*Configure GPIO pins : Y_CCW_Pin X_CW_Pin */
  GPIO_InitStruct.Pin = Y_CCW_Pin|X_CW_Pin;
  GPIO_InitStruct.Mode = GPIO_MODE_OUTPUT_PP;
  GPIO_InitStruct.Pull = GPIO_NOPULL;
  GPIO_InitStruct.Speed = GPIO_SPEED_FREQ_VERY_HIGH;
  HAL_GPIO_Init(GPIOB, &GPIO_InitStruct);

  /*Configure GPIO pin : X_CCW_Pin */
  GPIO_InitStruct.Pin = X_CCW_Pin;
  GPIO_InitStruct.Mode = GPIO_MODE_OUTPUT_PP;
  GPIO_InitStruct.Pull = GPIO_NOPULL;
  GPIO_InitStruct.Speed = GPIO_SPEED_FREQ_VERY_HIGH;
  HAL_GPIO_Init(X_CCW_GPIO_Port, &GPIO_InitStruct);

  /*Configure GPIO pins : X_L1_Pin X_L2_Pin X_L3_Pin X_L4_Pin
                           X_HM_Pin T_HEAD_Pin T_VAC_Pin */
  GPIO_InitStruct.Pin = X_L1_Pin|X_L2_Pin|X_L3_Pin|X_L4_Pin
                          |X_HM_Pin|T_HEAD_Pin|T_VAC_Pin;
  GPIO_InitStruct.Mode = GPIO_MODE_INPUT;
  GPIO_InitStruct.Pull = GPIO_PULLUP;
  HAL_GPIO_Init(GPIOD, &GPIO_InitStruct);

  /*Configure GPIO pins : READY_OUT_Pin DSTART__Pin VAC_Pin HEAD_Pin
                           ROT_Pin CENTERING_Pin */
  GPIO_InitStruct.Pin = READY_OUT_Pin|DSTART__Pin|VAC_Pin|HEAD_Pin
                          |ROT_Pin|CENTERING_Pin;
  GPIO_InitStruct.Mode = GPIO_MODE_OUTPUT_PP;
  GPIO_InitStruct.Pull = GPIO_NOPULL;
  GPIO_InitStruct.Speed = GPIO_SPEED_FREQ_LOW;
  HAL_GPIO_Init(GPIOD, &GPIO_InitStruct);

  /*Configure GPIO pins : SP_G_Pin SP_F_Pin SP_E_Pin SENSORDRV_Pin
                           V_CNG_Pin A_CENT_Pin PULSE_Pin */
  GPIO_InitStruct.Pin = SP_G_Pin|SP_F_Pin|SP_E_Pin|SENSORDRV_Pin
                          |V_CNG_Pin|A_CENT_Pin|PULSE_Pin;
  GPIO_InitStruct.Mode = GPIO_MODE_OUTPUT_PP;
  GPIO_InitStruct.Pull = GPIO_NOPULL;
  GPIO_InitStruct.Speed = GPIO_SPEED_FREQ_LOW;
  HAL_GPIO_Init(GPIOG, &GPIO_InitStruct);

  /*Configure GPIO pins : STP2_STP_Pin STP1_STP_Pin */
  GPIO_InitStruct.Pin = STP2_STP_Pin|STP1_STP_Pin;
  GPIO_InitStruct.Mode = GPIO_MODE_AF_PP;
  GPIO_InitStruct.Pull = GPIO_NOPULL;
  GPIO_InitStruct.Speed = GPIO_SPEED_FREQ_LOW;
  GPIO_InitStruct.Alternate = GPIO_AF2_TIM4;
  HAL_GPIO_Init(GPIOB, &GPIO_InitStruct);

}

/* USER CODE BEGIN 4 */
#if defined (STM32F103C8)
void _delay_ms(uint32_t x)
{
	u32 temp;
	SysTick->LOAD = (u32)72000000 / 8000;                     // Loading time
	SysTick->VAL = 0x00;                                            // Empty the counter
	SysTick->CTRL = 0x01;                                           // Start from bottom
	do
	{
		temp = SysTick->CTRL;
	} while (temp & 0x01 && !(temp&(1 << 16)));                             // Wait time arrive
	SysTick->CTRL = 0x00;                                            // Close the counter
	SysTick->VAL = 0X00;                                            // Empty the counter
}
void LedBlink(void)
{
	static BitAction nOnFlag = Bit_SET;
	GPIO_WriteBit(GPIOC, GPIO_Pin_13, nOnFlag);
	nOnFlag = (nOnFlag == Bit_SET) ? Bit_RESET : Bit_SET;
}
#endif
#if defined (STM32F407xx)
void _delay_ms(uint32_t x)
{
	uint32_t time = HAL_GetTick() + x;
	while (HAL_GetTick() < time);                             // Wait time arrive
}
#ifdef LEDBLINK
void LedBlink(void)
{
	HAL_GPIO_TogglePin()
	static BitAction nOnFlag = Bit_SET;
	GPIO_WriteBit(GPIOC, GPIO_Pin_13, nOnFlag);
	nOnFlag = (nOnFlag == Bit_SET) ? Bit_RESET : Bit_SET;
}
#endif
#endif

/* USER CODE END 4 */

void Error_Handler(void)
{
}

/************************ (C) COPYRIGHT STMicroelectronics *****END OF FILE****/
